# PIC32MM0064GPL020 device description
Architecture: MIPS; Family: PIC32MM1324; Series: PIC32MM
Registers are 32-bit, read-write, no defined reset value unless marked. A register's access mark holds for its fields unless they carry their own. Offsets are from the block's base; [hi:lo] are bit positions; {n}, {i} and the like mark numbered series; 'fields as' and 'values as' point back to an identical list.

## CCP
Instances: CCP 0x1f800100 in periph0
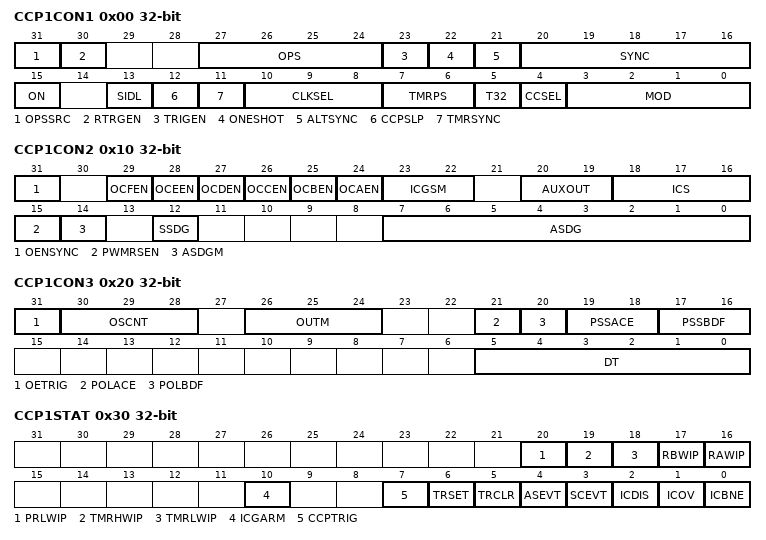
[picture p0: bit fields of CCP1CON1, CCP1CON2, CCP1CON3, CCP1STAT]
0x00 CCP1CON1
  [31] OPSSRC
  [30] RTRGEN
  [27:24] OPS
    0=Each time base period match or input capture event; 1=Every 2nd time base period match or 2nd input capture event; 2=Every 3rd time base period match or 3rd input capture event; 3=Every 4th time base period match or 4th input capture event; {v}=Every {v+1}th time base period match (v=4..15)
  [23] TRIGEN
  [22] ONESHOT
  [21] ALTSYNC
  [20:16] SYNC
    0=No external synchronization; 1=This MCCP/SCCP; 2=MCCP1; 3=SCCP2; 4=SCCP3; {v}=INT{v-9} pin (v=9..13); 16=CLC1; 17=CLC2; 24=Comparator 1; 25=Comparator 2; 27=Start of ADC conversion; 31=Free running mode and rolls over at FFFFh (Timer period ignored)
  [15] ON
  [13] SIDL
  [12] CCPSLP
  [11] TMRSYNC
  [10:8] CLKSEL
    0=System Clock (Fsys); 1=REFCLKO Output Clock; 2=Secondary Oscillator Clock (SOSC); 3=CLC1 output; 6=TCKIB Pin (remappable); 7=TCKIA Pin (remappable)
  [7:6] TMRPS
  [5] T32
  [4] CCSEL
  [3:0] MOD
0x10 CCP1CON2
  [31] OENSYNC
    0=Update by output enable bits occurs immediately; 1=Update by output enable bits occurs on the next Time Base Reset or Rollover
  [29] OCFEN
  [28] OCEEN
  [27] OCDEN
  [26] OCCEN
  [25] OCBEN
  [24] OCAEN
  [23:22] ICGSM
  [20:19] AUXOUT
  [18:16] ICS
    0=ICM1 pin (remappable); 1=Comparator 1 Output; 2=Comparator 2 Output; 4=CLC1 Output; 5=CLC2 Output
  [15] PWMRSEN
    0=ASEVT must be cleared in software to resume PWM activity; 1=ASEVT bit clears automatically at the beginning of next PWM period, after shutdown input has ended
  [14] ASDGM
    0=Shutdown event occurs immediately; 1=Waits until the next time base reset or rollover
  [12] SSDG
  [7:0] ASDG
    0=Disabled; 1=Comparator 1; 2=Comparator 2; 8=SCCP3 output; 16=SCCP2 output; 32=CLC1 output; 64=OCFA pin (remappable); 128=OCFB pin (remappable)
0x20 CCP1CON3
  [31] OETRIG
  [30:28] OSCNT
  [26:24] OUTM
  [21] POLACE
  [20] POLBDF
  [19:18] PSSACE
    0=Pins are in high impedance state; 2=Pins are driven inactive; 3=Pins are driven active
  [17:16] PSSBDF
  [5:0] DT
0x30 CCP1STAT
  [20] PRLWIP, [19] TMRHWIP, [18] TMRLWIP, [17] RBWIP, [16] RAWIP, [10] ICGARM, [7] CCPTRIG, [6] TRSET, [5] TRCLR, [4] ASEVT, [3] SCEVT, [2] ICDIS, [1] ICOV, [0] ICBNE
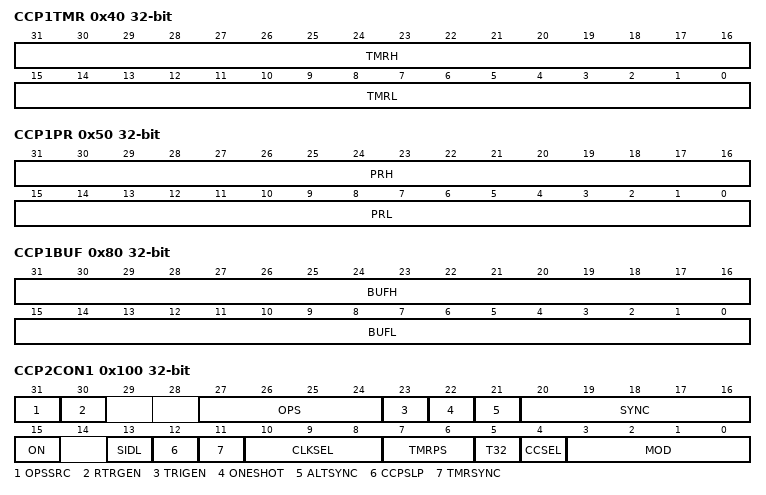
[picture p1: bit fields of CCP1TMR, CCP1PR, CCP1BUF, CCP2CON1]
0x40 CCP1TMR
  [31:16] TMRH, [15:0] TMRL
0x50 CCP1PR
  [31:16] PRH, [15:0] PRL
0x60 CCP1RA
  [15:0] CMPA
0x70 CCP1RB
  [15:0] CMPB
0x80 CCP1BUF
  [31:16] BUFH, [15:0] BUFL
0x100 CCP2CON1
  [31] OPSSRC
  [30] RTRGEN
  [27:24] OPS
  [23] TRIGEN
  [22] ONESHOT
  [21] ALTSYNC
  [20:16] SYNC
  [15] ON
  [13] SIDL
  [12] CCPSLP
  [11] TMRSYNC
  [10:8] CLKSEL
    values as CCP1CON1.CLKSEL
  [7:6] TMRPS
  [5] T32
  [4] CCSEL
  [3:0] MOD
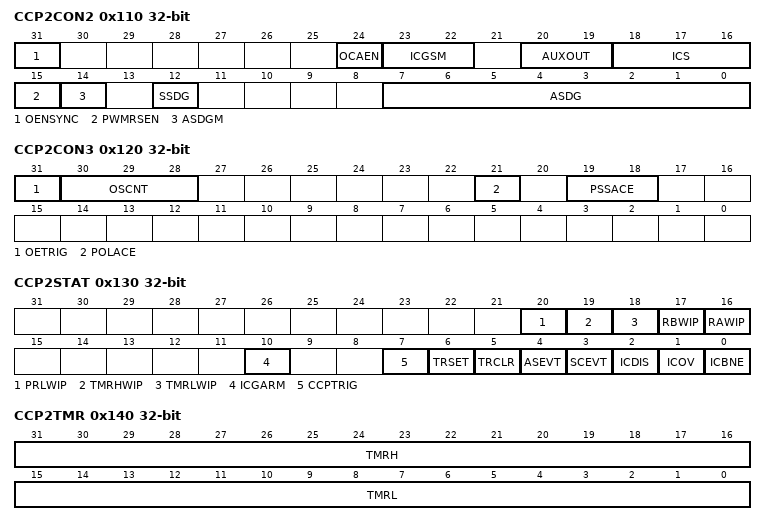
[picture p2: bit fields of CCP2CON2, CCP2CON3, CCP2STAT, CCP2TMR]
0x110 CCP2CON2
  [31] OENSYNC
  [24] OCAEN
  [23:22] ICGSM
  [20:19] AUXOUT
  [18:16] ICS
    0=ICM2 pin (remappable); 1=Comparator 1 Output; 2=Comparator 2 Output; 4=CLC1 Output; 5=CLC2 Output
  [15] PWMRSEN
  [14] ASDGM
  [12] SSDG
  [7:0] ASDG
    0=Disabled; 1=Comparator 1; 2=Comparator 2; 8=SCCP3 output; 16=MCCP1 output; 32=CLC1 output; 64=OCFA pin (remappable); 128=OCFB pin (remappable)
0x120 CCP2CON3
  [31] OETRIG, [30:28] OSCNT, [21] POLACE, [19:18] PSSACE
0x130 CCP2STAT
  fields as CCP1STAT
0x140 CCP2TMR
  [31:16] TMRH, [15:0] TMRL
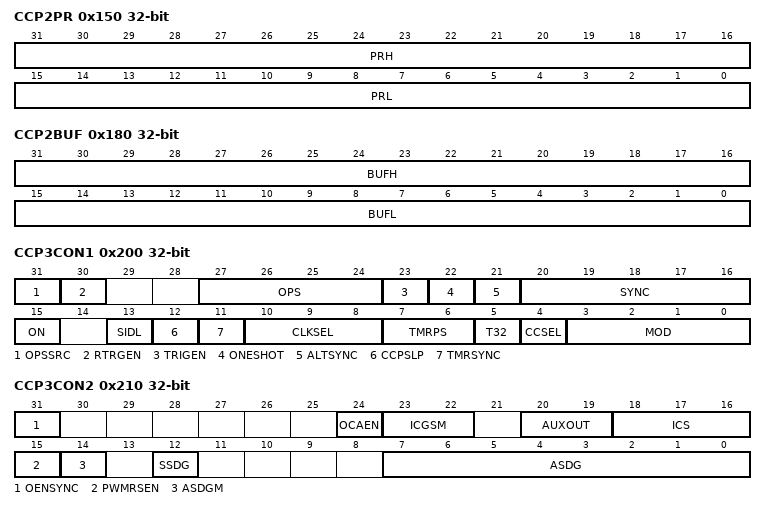
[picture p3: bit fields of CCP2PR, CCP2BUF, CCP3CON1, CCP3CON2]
0x150 CCP2PR
  [31:16] PRH, [15:0] PRL
0x160 CCP2RA
  [15:0] CMPA
0x170 CCP2RB
  [15:0] CMPB
0x180 CCP2BUF
  [31:16] BUFH, [15:0] BUFL
0x200 CCP3CON1
  [31] OPSSRC
  [30] RTRGEN
  [27:24] OPS
  [23] TRIGEN
  [22] ONESHOT
  [21] ALTSYNC
  [20:16] SYNC
  [15] ON
  [13] SIDL
  [12] CCPSLP
  [11] TMRSYNC
  [10:8] CLKSEL
    0=System Clock (Fsys); 1=REFCLKO Output Clock; 2=Secondary Oscillator Clock (SOSC); 3=CLC2 output; 6=TCKIB Pin (remappable); 7=TCKIA Pin (remappable)
  [7:6] TMRPS
  [5] T32
  [4] CCSEL
  [3:0] MOD
0x210 CCP3CON2
  [31] OENSYNC
  [24] OCAEN
  [23:22] ICGSM
  [20:19] AUXOUT
  [18:16] ICS
    0=ICM3 pin (remappable); 1=Comparator 1 Output; 2=Comparator 2 Output; 4=CLC1 Output; 5=CLC2 Output
  [15] PWMRSEN
  [14] ASDGM
  [12] SSDG
  [7:0] ASDG
    0=Disabled; 1=Comparator 1; 2=Comparator 2; 8=SCCP2 output; 16=MCCP1 output; 32=CLC2 output; 64=OCFA pin (remappable); 128=OCFB pin (remappable)
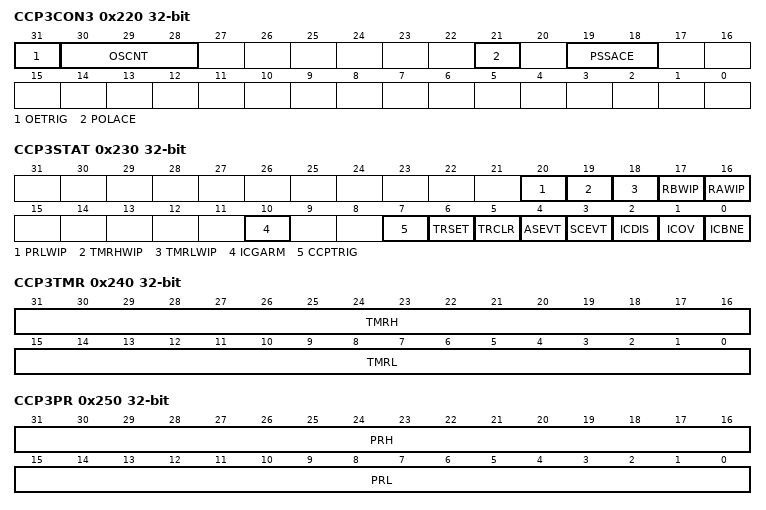
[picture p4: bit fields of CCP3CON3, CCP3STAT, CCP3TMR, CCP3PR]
0x220 CCP3CON3
  [31] OETRIG, [30:28] OSCNT, [21] POLACE, [19:18] PSSACE
0x230 CCP3STAT
  fields as CCP1STAT
0x240 CCP3TMR
  [31:16] TMRH, [15:0] TMRL
0x250 CCP3PR
  [31:16] PRH, [15:0] PRL
0x260 CCP3RA
  [15:0] CMPA
0x270 CCP3RB
  [15:0] CMPB
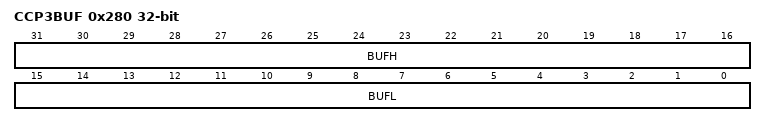
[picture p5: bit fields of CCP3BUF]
0x280 CCP3BUF
  [31:16] BUFH, [15:0] BUFL
Value list CCP1CON1__TMRPS: 0=1:1 prescale; 1=1:4 prescale; 2=1:16 prescale; 3=1:64 prescale
Value list CCP1CON3__POLACE: 0=Output pin polarity is active-high; 1=Output pin polarity is active-low

## Notices in the file
Copyright (c) 2019 Microchip Technology Inc.
SPDX-License-Identifier: Apache-2.0
Licensed under the Apache License, Version 2.0 (the "License");
you may not use this file except in compliance with the License.
You may obtain a copy of the License at
http://www.apache.org/licenses/LICENSE-2.0
Unless required by applicable law or agreed to in writing, software
distributed under the License is distributed on an "AS IS" BASIS,
WITHOUT WARRANTIES OR CONDITIONS OF ANY KIND, either express or implied.
See the License for the specific language governing permissions and
limitations under the License.
